# TLE987x register map
Vendor: Infineon; File version: 4.2
CPU: CM3 r0p0, little endian, no MPU, no FPU, 4 interrupt priority bits
Registers are 32-bit, read-write, reset 0x0 unless marked. A register's access mark holds for its fields unless they carry their own. Offsets are from the block's base; [hi:lo] are bit positions; {n}, {i} and the like mark numbered series; 'fields as' and 'values as' point back to an identical list.

## SCU — System Control Unit
Base 0x50005000
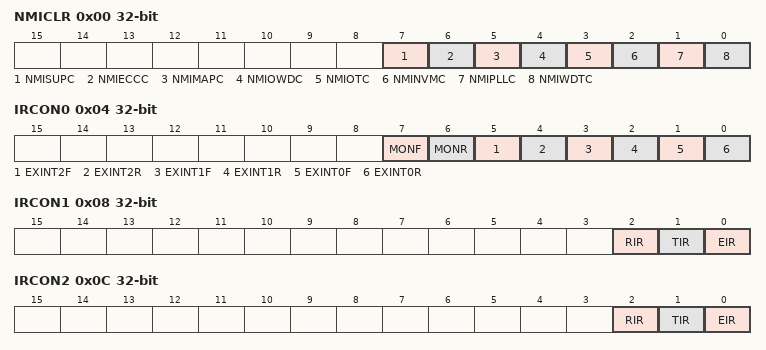
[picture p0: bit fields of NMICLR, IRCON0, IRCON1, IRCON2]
0x00 NMICLR wo — NMI Clear Register, RESET_TYPE_3
  [7] NMISUPC — Supply Prewarning NMI Clear
    0=Supply NMI is not cleared; 1=Supply NMI is cleared
  [6] NMIECCC — ECC Error NMI Clear
    0=ECC Error NMI is not cleared; 1=ECC Error NMI is cleared
  [5] NMIMAPC — NVM Map Error NMI Clear
    0=NVM Map Error NMI is not cleared; 1=NVM Map Error NMI is cleared
  [4] NMIOWDC — Oscillator Watchdog NMI Clear
    0=Oscillator watchdog NMI is not cleared; 1=Oscillator watchdog NMI is cleared
  [3] NMIOTC — NMI OT Clear
    0=NMI OT is not cleared; 1=NMI OT is cleared
  [2] NMINVMC — NVM Operation Complete NMI Clear
    0=NVM operation complete NMI is not cleared; 1=NVM operation complete NMI is cleared
  [1] NMIPLLC — PLL Loss of Lock NMI Clear
    0=PLL Loss of Lock NMI is not cleared; 1=PLL Loss of Lock NMI is cleared
  [0] NMIWDTC — Watchdog Timer NMI Clear
    0=WDT NMI is not cleared; 1=WDT NMI is cleared
0x04 IRCON0 ro — Interrupt Request Register 0, RESET_TYPE_3
  [7] MONF — Interrupt Flag for External Interrupt MON on falling edge
    0=Interrupt on falling edge event has not occurred; 1=Interrupt on falling edge event has occurred
  [6] MONR — Interrupt Flag for External Interrupt MON on rising edge
    0=Interrupt on rising edge event has not occurred; 1=Interrupt on rising edge event has occurred
  [5] EXINT2F — Interrupt Flag for External Interrupt 2x on falling edge
    values as MONF
  [4] EXINT2R — Interrupt Flag for External Interrupt 2x on rising edge
    values as MONR
  [3] EXINT1F — Interrupt Flag for External Interrupt 1x on falling edge
    values as MONF
  [2] EXINT1R — Interrupt Flag for External Interrupt 1x on rising edge
    values as MONR
  [1] EXINT0F — Interrupt Flag for External Interrupt 0x on falling edge
    values as MONF
  [0] EXINT0R — Interrupt Flag for External Interrupt 0x on rising edge
    values as MONR
0x08 IRCON1 ro — Interrupt Request Register 1, RESET_TYPE_3
  [all] fields
    0=Interrupt event has not occurred; 1=Interrupt event has occurred
  [2] RIR — Receive Interrupt Flag for SSC1
  [1] TIR — Transmit Interrupt Flag for SSC1
  [0] EIR — Error Interrupt Flag for SSC1
0x0C IRCON2 ro — Interrupt Request Register 2, RESET_TYPE_3
  [all] fields
    values as the fields of IRCON1
  [2] RIR — Receive Interrupt Flag for SSC2
  [1] TIR — Transmit Interrupt Flag for SSC2
  [0] EIR — Error Interrupt Flag for SSC2
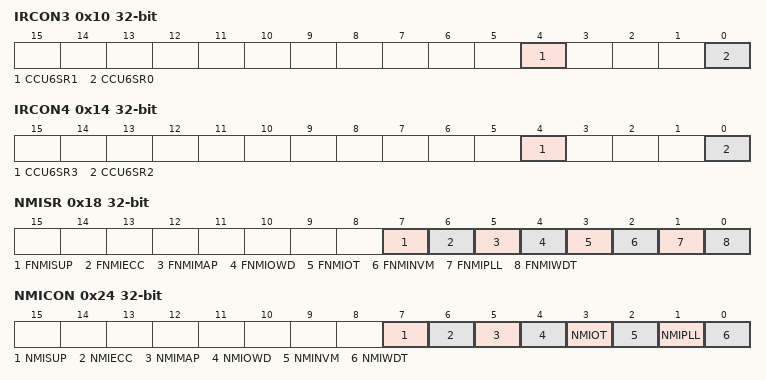
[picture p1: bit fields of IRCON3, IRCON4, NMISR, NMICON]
0x10 IRCON3 ro — Interrupt Request Register 3, RESET_TYPE_3
  [4] CCU6SR1 — Interrupt Flag 1 for CCU6
    values as the fields of IRCON1
  [0] CCU6SR0 — Interrupt Flag 0 for CCU6
    values as the fields of IRCON1
0x14 IRCON4 ro — Interrupt Request Register 4, RESET_TYPE_3
  [4] CCU6SR3 — Interrupt Flag 3 for CCU6
    values as the fields of IRCON1
  [0] CCU6SR2 — Interrupt Flag 2 for CCU6
    values as the fields of IRCON1
0x18 NMISR ro — NMI Status Register, RESET_TYPE_4
  [7] FNMISUP — Supply Prewarning NMI Flag
    0=No supply prewarning NMI has occurred; 1=Supply prewarning has occurred
  [6] FNMIECC — ECC Error NMI Flag
    0=No uncorrectable ECC error has occurred on NVM, XRAM; 1=Uncorrectable ECC error has occurred on NVM, RAM
  [5] FNMIMAP — NVM Map Error NMI Flag
    0=No NVM Map Error NMI has occurred; 1=NVM Map Error has occurred
  [4] FNMIOWD — Oscillator Watchdog or MI_CLK Watchdog NMI Flag
    0=No oscillator / MI_CLK watchdog NMI has occurred; 1=Oscillator / MI_CLK watchdog event has occurred
  [3] FNMIOT — Over-temperature NMI Flag
    0=No OT NMI has occurred; 1=OT NMI event has occurred
  [2] FNMINVM — NVM Operation Complete NMI Flag
    0=No NVM NMI has occurred; 1=NVM operation complete event has occurred
  [1] FNMIPLL — PLL NMI Flag
    0=No PLL NMI has occurred; 1=PLL loss-of-lock has occurred
  [0] FNMIWDT — Watchdog Timer NMI Flag
    0=No watchdog NMI has occurred; 1=WDT prewarning has occurred
0x1C IEN0 — Interrupt Enable Register 0, RESET_TYPE_4
  [7] EA — Global Interrupt Mask
    0=All pending interrupt requests (except NMI) are blocked from the core; 1=Pending interrupt requests are not blocked from the core
0x24 NMICON — NMI Control Register, RESET_TYPE_4
  [7] NMISUP — Supply Prewarning NMI Enable
    0=Supply NMI is disabled; 1=Supply NMI is enabled
  [6] NMIECC — ECC Error NMI Enable
    0=ECC Error NMI is disabled; 1=ECC Error NMI is enabled
  [5] NMIMAP — NVM Map Error NMI Enable
    0=NVM Map Error NMI is disabled; 1=NVM Map Error NMI is enabled
  [4] NMIOWD — Oscillator Watchdog NMI Enable
    0=Oscillator watchdog NMI is disabled; 1=Oscillator watchdog NMI is enabled
  [3] NMIOT — NMI OT Enable
    0=NMI OT is disabled; 1=NMI OT is enabled
  [2] NMINVM — NVM Operation Complete NMI Enable
    0=NVM operation complete NMI is disabled; 1=NVM operation complete NMI is enabled
  [1] NMIPLL — PLL Loss of Lock NMI Enable
    0=PLL Loss of Lock NMI is disabled; 1=PLL Loss of Lock NMI is enabled
  [0] NMIWDT — Watchdog Timer NMI Enable
    0=WDT NMI is disabled; 1=WDT NMI is enabled
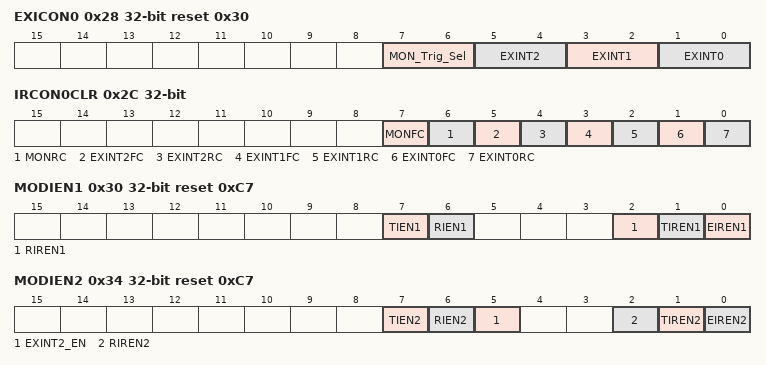
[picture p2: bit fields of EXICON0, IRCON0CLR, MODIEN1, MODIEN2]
0x28 EXICON0 reset 0x30 — External Interrupt Control Register 0, RESET_TYPE_3
  [7:6] MON_Trig_Sel — MON Input Trigger Select
    0=external interrupt MON is disabled; 1=Interrupt on rising edge; 2=Interrupt on falling edge; 3=Interrupt on both rising and falling edge
  [5:4] EXINT2 — External Interrupt 2 Trigger Select
    0=external interrupt 2 is disabled; 1=Interrupt on rising edge; 2=Interrupt on falling edge; 3=Interrupt on both rising and falling edge
  [3:2] EXINT1 — External Interrupt 1 Trigger Select
    0=external interrupt 1 is disabled; 1=Interrupt on rising edge; 2=Interrupt on falling edge; 3=Interrupt on both rising and falling edge
  [1:0] EXINT0 — External Interrupt 0 Trigger Select
    0=external interrupt 0 is disabled; 1=Interrupt on rising edge; 2=Interrupt on falling edge; 3=Interrupt on both rising and falling edge
0x2C IRCON0CLR wo — Interrupt Request 0 Clear Register, RESET_TYPE_3
  [7] MONFC — Interrupt Flag for External Interrupt MON on falling edge clear
    0=Interrupt on falling edge event is not cleared; 1=Interrupt on falling edge event is cleared
  [6] MONRC — Interrupt Flag for External Interrupt MON on rising edge clear
    0=Interrupt on rising edge event is not cleared; 1=Interrupt on rising edge event is cleared
  [5] EXINT2FC — Interrupt Flag for External Interrupt 2x on falling edge clear
    values as MONFC
  [4] EXINT2RC — Interrupt Flag for External Interrupt 2x on rising edge clear
    values as MONRC
  [3] EXINT1FC — Interrupt Flag for External Interrupt 1x on falling edge clear
    values as MONFC
  [2] EXINT1RC — Interrupt Flag for External Interrupt 1x on rising edge clear
    values as MONRC
  [1] EXINT0FC — Interrupt Flag for External Interrupt 0x on falling edge clear
    values as MONFC
  [0] EXINT0RC — Interrupt Flag for External Interrupt 0x on rising edge clear
    values as MONRC
0x30 MODIEN1 reset 0xC7 — Peripheral Interrupt Enable Register 1, RESET_TYPE_3
  [7] TIEN1 — UART 1 Transmit Interrupt Enable
    0=Transmit interrupt is disabled; 1=Transmit interrupt is enabled
  [6] RIEN1 — UART 1 Receive Interrupt Enable
    0=Receive interrupt is disabled; 1=Receive interrupt is enabled
  [2] RIREN1 — SSC 1 Receive Interrupt Enable
    values as RIEN1
  [1] TIREN1 — SSC 1 Transmit Interrupt Enable
    values as TIEN1
  [0] EIREN1 — SSC 1 Error Interrupt Enable
    0=Error interrupt is disabled; 1=Error interrupt is enabled
0x34 MODIEN2 reset 0xC7 — Peripheral Interrupt Enable Register 2, RESET_TYPE_3
  [7] TIEN2 — UART 2 Transmit Interrupt Enable
    values as MODIEN1.TIEN1
  [6] RIEN2 — UART 2 Receive Interrupt Enable
    values as MODIEN1.RIEN1
  [5] EXINT2_EN — External Interrupt 2 Enable
    0=External interrupt is disabled; 1=External interrupt is enabled
  [2] RIREN2 — SSC 2 Receive Interrupt Enable
    values as MODIEN1.RIEN1
  [1] TIREN2 — SSC 2 Transmit Interrupt Enable
    values as MODIEN1.TIEN1
  [0] EIREN2 — SSC 2 Error Interrupt Enable
    0=Error interrupt is disabled; 1=Error interrupt is enabled
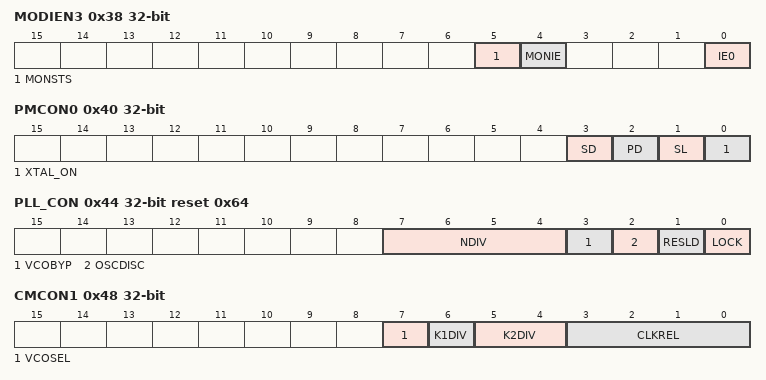
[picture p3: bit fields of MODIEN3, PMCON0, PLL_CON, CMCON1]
0x38 MODIEN3 access per field — Peripheral Interrupt Enable Register 3, RESET_TYPE_3
  [5] MONSTS ro — MON Input Status
    0=Status zero; 1=Status one
  [4] MONIE rw — MON Interrupt Enable
    0=disabled; 1=enabled
  [0] IE0 rw — External Interrupt Enable
    0=disabled; 1=enabled
0x3C MODIEN4 — Peripheral Interrupt Enable Register 4, RESET_TYPE_3
  [0] IE1 — External Interrupt Enable
    0=disabled; 1=enabled
0x40 PMCON0 — Power Mode Control Register 0, RESET_TYPE_3
  [3] SD — Slow Down Mode Enable. Active High.
    0=DISABLED (Slow Down disabled); 1=ENABLED (Slow Down enabled)
  [2] PD — Power Down Mode Enable. Active High.
    0=DISABLED (Power Down disabled); 1=ENABLED (Power Down enabled)
  [1] SL — Sleep Mode Enable. Active High.
    0=DISABLED (Sleep Mode disabled); 1=ENABLED (Sleep Mode enabled)
  [0] XTAL_ON — OSC_HP Operation in Power Down Mode
    0=OSC_HP (XTAL) will be put to Power Down mode by hardware in power save mode; 1=OSC_HP (XTAL) continues to operate in Power Down mode, if enabled by SCU_OSC_CON.XPD
0x44 PLL_CON access per field reset 0x64 — PLL Control Register, RESET_TYPE_4
  [7:4] NDIV rw — PLL N-Divider
    0=N = 8; 1=N = 9; 2=N = 10; 3=N = 12; 4=N = 14; 5=N = 15; 6=N = 16 (default); 7=N = 18; 8=N = 20; 9=N = 21; 10=N = 22; {v}=N = {v+13} (v=11..15)
  [3] VCOBYP rw — PLL VCO Bypass Mode Select
    0=Normal (or freerunning) operation (default); 1=Prescaler Mode; VCO is bypassed (PLL output clock is derived from input clock divided by K1-divider)
  [2] OSCDISC rw — Oscillator Disconnect
    0=Oscillator is connected to the PLL; 1=Oscillator is disconnected to the PLL
  [1] RESLD rw — Restart Lock Detection
    0=No effect; 1=Reset lock flag and restart lock detection
  [0] LOCK ro — PLL Lock Status Flag
    0=The frequency difference of fREF and fDIV is greater than allowed. The VCO part of the PLL can not lock on a target frequency.; 1=The frequency difference of fREF and fDIV is small enough to enable a stable VCO operation
0x48 CMCON1 — Clock Control Register 1, RESET_TYPE_4
  [7] VCOSEL — VCOSEL Setting
    0=VCOSEL = 0; 1=VCOSEL = 1
  [6] K1DIV — PLL K1-Divider
    0=K1 = 2; 1=K1 = 1
  [5:4] K2DIV — PLL K2-Divider
    {v}=K2 = {v+2} (v=0..3)
  [3:0] CLKREL — Slow Down Clock Divider for fCCLK Generation
    0=fsys; 1=fsys/2; 2=fsys/3; 3=fsys/4; 4=fsys/8; 5=fsys/16; 6=fsys/24; 7=fsys/32; 8=fsys/48; 9=fsys/64; 10=fsys/96; 11=fsys/128; 12=fsys/192; 13=fsys/256; 14=fsys/384; 15=fsys/512
0x4C CMCON2 — Clock Control Register 2, RESET_TYPE_4
  [0] PBA0CLKREL — PBA0 Clock Divider
    0=divide by 1; 1=divide by 2
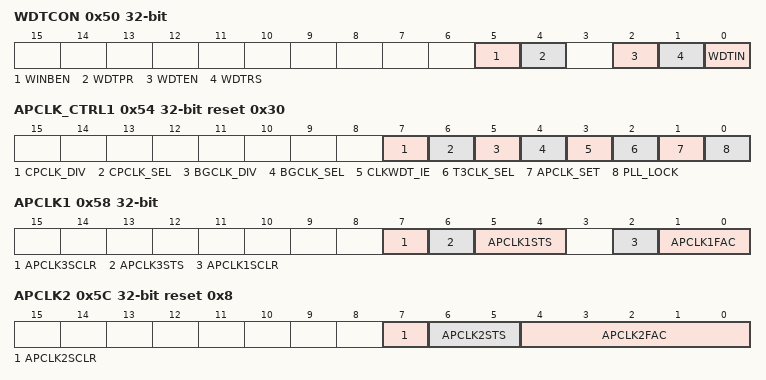
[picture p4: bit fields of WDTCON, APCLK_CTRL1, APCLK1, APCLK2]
0x50 WDTCON access per field — Watchdog Timer Control Register, RESET_TYPE_3
  [5] WINBEN rw — Watchdog Window-Boundary Enable
    0=Watchdog Window-Boundary feature is disabled. (default); 1=Watchdog Window-Boundary feature is enabled
  [4] WDTPR ro — Watchdog Prewarning Mode Flag
    0=Normal mode (default after reset); 1=The Watchdog is operating in Prewarning Mode
  [2] WDTEN rw — WDT Enable
    0=WDT is disabled; 1=WDT is enabled
  [1] WDTRS rw — WDT Refresh Start
    0=no_action (WDT not triggered); 1=refresh (WDT refresh is triggered)
  [0] WDTIN rw — Watchdog Timer Input Frequency Selection
    0=Input frequency is fPCLK/2; 1=Input frequency is fPCLK/128
0x54 APCLK_CTRL1 access per field reset 0x30 — Analog Peripheral Clock Control 1 Register, RESET_TYPE_4
  [7] CPCLK_DIV rw — Charge Pump Clock Divider
    0=divide by 2; 1=divide by 1
  [6] CPCLK_SEL rw — Charge Pump Clock Selection
    0=LP_CLK is selected; 1=fsys is selected
  [5] BGCLK_DIV rw — Bandgap Clock Divider
    0=divide by 2; 1=divide by 1
  [4] BGCLK_SEL rw — Bandgap Clock Selection
    0=LP_CLK is selected; 1=fsys is selected
  [3] CLKWDT_IE rw — Clock Watchdog Interrupt Enable
    0=Interrupt disabled; 1=Interrupt enabled
  [2] T3CLK_SEL rw — Timer 3 Clock Selection
    0=LP_CLK is selected; 1=MI_CLK is selected
  [1] APCLK_SET rw — Set and Overtake Flag for Clock Settings
    0=Clock Settings are ignored (previous values are hold); 1=Clock Settings Settings are overtaken
  [0] PLL_LOCK ro — PLL Lock Indicator
    1=locked (PLL has locked); 0=not_locked (PLL not locked)
0x58 APCLK1 access per field — Analog Peripheral Clock Register 1, RESET_TYPE_4
  [7] APCLK3SCLR rw — Analog Peripherals Clock Status Clear
    0=no_action (no change); 1=clear status
  [6] APCLK3STS ro — Loss of Clock Status
    0=No loss of clock; 1=Loss of Lock occured
  [5:4] APCLK1STS ro — Analog Peripherals Clock Status
    0=The MI_CLK clock is in the required range; 1=The MI_CLK clock exceeds the higher limit; 2=The MI_CLK clock exceeds the lower limit; 3=The MI_CLK clock is not inside the specified limit
  [2] APCLK1SCLR rw — Analog Peripherals Clock Status Clear
    0=no_action (no change); 1=clear status
  [1:0] APCLK1FAC rw — Analog Module Clock Factor
    {v}=Divide by {v+1} (v=0..3)
0x5C APCLK2 access per field reset 0x8 — Analog Peripheral Clock Register 2, RESET_TYPE_4
  [7] APCLK2SCLR rw — Analog Peripherals Clock Status Clear
    0=no_action (no change); 1=clear status
  [6:5] APCLK2STS ro — Analog Peripherals Clock Status
    0=The TFILT_CLK clock is in the required range; 1=The TFILT_CLK clock exceeds the higher limit; 2=The TFILT_CLK clock exceeds the lower limit; 3=The TFILT_CLK clock is not inside the specified limit
  [4:0] APCLK2FAC rw — Slow Down Clock Divider for TFILT_CLK Generation
    0=fsys; {v}=fsys/{v+1} (v=1..11); 30=fsys/31; 31=fsys/32
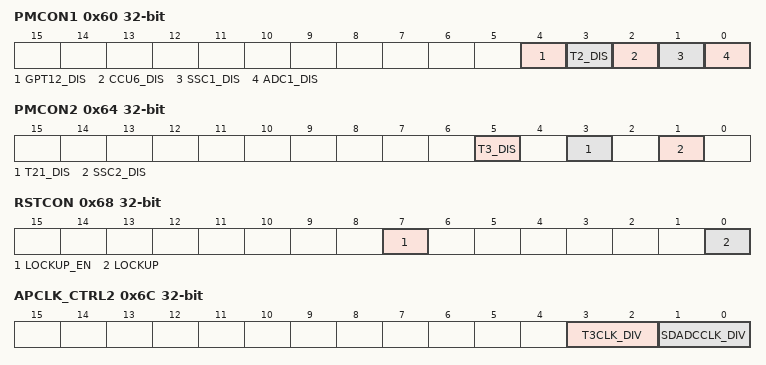
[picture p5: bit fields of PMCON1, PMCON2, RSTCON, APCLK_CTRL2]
0x60 PMCON1 — Peripheral Management Control Register 1, RESET_TYPE_3
  [4] GPT12_DIS — General Purpose Timer 12 Disable Request. Active high.
    0=GPT12is in normal operation. (default); 1=Request to disable the GPT12
  [3] T2_DIS — T2 Disable Request. Active high.
    0=T2 is in normal operation. (default); 1=Request to disable the T2
  [2] CCU6_DIS — CCU6 Disable Request. Active high.
    0=CCU6 is in normal operation. (default); 1=Request to disable the CCU6
  [1] SSC1_DIS — SSC1 Disable Request. Active high.
    0=SSC1 is in normal operation. (default); 1=Request to disable the SSC1
  [0] ADC1_DIS — ADC1 Disable Request. Active high.
    0=ADC1 is in normal operation. (default); 1=Request to disable the ADC
0x64 PMCON2 — Peripheral Management Control Register 2, RESET_TYPE_3
  [5] T3_DIS — T3 Disable Request. Active high.
    0=T3is in normal operation. (default); 1=Request to disable the T3
  [3] T21_DIS — T21 Disable Request. Active high.
    0=T21 is in normal operation. (default); 1=Request to disable the T21
  [1] SSC2_DIS — SSC2 Disable Request. Active high.
    0=SSC2 is in normal operation. (default); 1=Request to disable the SSC2
0x68 RSTCON — Reset Control Register, RESET_TYPE_3
  [7] LOCKUP_EN — Lockup Reset Enable Flag
    0=Lockup is disabled; 1=Lockup is enabled
  [0] LOCKUP — Lockup Flag
    0=Lockup Status not active; 1=Lockup Status active
0x6C APCLK_CTRL2 — Analog Peripheral Clock Control 2 Register, RESET_TYPE_4
  [3:2] T3CLK_DIV — Timer 3 Clock Divider
    0=divide by 1; 1=divide by 2; 2=divide by 4; 3=divide by 8
  [1:0] SDADCCLK_DIV — SD-ADC Clock Divider
    0=divide by 1; 1=divide by 2; 2=divide by 4; 3=divide by 8
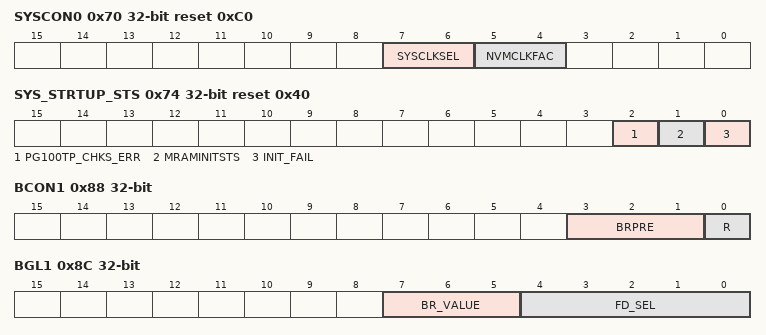
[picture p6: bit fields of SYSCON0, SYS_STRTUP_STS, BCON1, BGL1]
0x70 SYSCON0 reset 0xC0 — System Control Register 0, RESET_TYPE_4
  [7:6] SYSCLKSEL — System Clock Select
    0=The PLL clock output signal fPLL is used; 1=The direct clock input from fOSC is used; 2=The direct low-precision clock input from fLP_CLK is used; 3=The direct low-precision clock input from fLP_CLK is used
  [5:4] NVMCLKFAC — NVM Access Clock Factor
    {v}=Divide by {v+1} (v=0..3)
0x74 SYS_STRTUP_STS reset 0x40 — System Startup Status Register
  [2] PG100TP_CHKS_ERR — 100 TP Page Checksum Error
    0=pass (no checksum error detected); 1=fail (100TP checksum error detected)
  [1] MRAMINITSTS — Map RAM Initialization Status
    0=pass (Map RAM initialization pass); 1=fail (Map RAM initialization finished with fails)
  [0] INIT_FAIL — Initialization at startup failed
    0=pass (no error during startup detected); 1=fail (at least one error during startup detected)
0x78 WDTREL — Watchdog Timer Reload Register, RESET_TYPE_3
  [7:0] WDTREL — Watchdog Timer Reload Value
0x7C WDTWINB — Watchdog Window-Boundary Count, RESET_TYPE_3
  [7:0] WDTWINB — Watchdog Window-Boundary Count Value
0x80 WDTL ro — Watchdog Timer, Low Byte, RESET_TYPE_3
  [7:0] WDT — Watchdog Timer Current Value
0x84 WDTH ro — Watchdog Timer, High Byte, RESET_TYPE_3
  [7:0] WDT — Watchdog Timer Current Value
0x88 BCON1 — Baud Rate Control Register 1, RESET_TYPE_3
  [3:1] BRPRE — Prescaler Bit
    0=fDIV = fPCLK; 1=fDIV = fPCLK/2; 2=fDIV = fPCLK/4; 3=fDIV = fPCLK/8; 4=fDIV = fPCLK/16; 5=fDIV = fPCLK/32
  [0] R — Baud Rate Generator Run Control Bit
    0=Baud-rate generator disabled; 1=Baud-rate generator enabled
0x8C BGL1 — Baud Rate Timer/Reload Register, Low Byte 1, RESET_TYPE_3
  [7:5] BR_VALUE — Baud Rate Timer/Reload Value
  [4:0] FD_SEL — Fractional Divider Selection
0x90 BGH1 — Baud Rate Timer/Reload Register, High Byte, RESET_TYPE_3
  [7:0] BR_VALUE — Baud Rate Timer/Reload Value
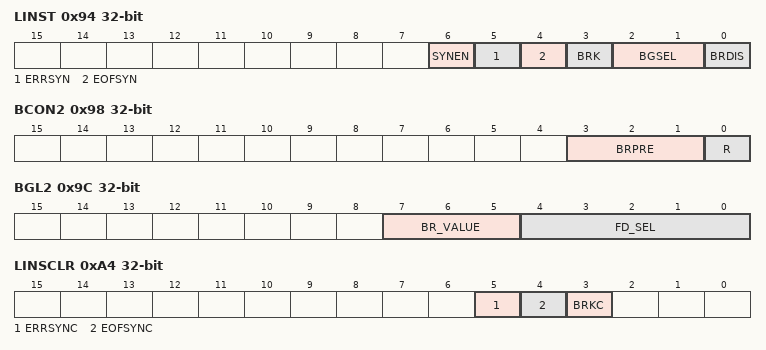
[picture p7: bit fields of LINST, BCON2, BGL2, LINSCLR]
0x94 LINST access per field — LIN Status Register, RESET_TYPE_3
  [6] SYNEN rw — End of SYN Byte and SYN Byte Error Interrupts Enable
    0=End of SYN Byte and SYN Byte Error Interrupts are not enabled; 1=End of SYN Byte and SYN Byte Error Interrupts are enabled
  [5] ERRSYN ro — SYN Byte Error Interrupt Flag
    0=Error is not detected in SYN Byte; 1=Error is detected in SYN Byte
  [4] EOFSYN ro — End of SYN Byte Interrupt Flag
    0=End of SYN Byte is not detected; 1=End of SYN Byte is detected
  [3] BRK ro — Break Field Flag
    0=Break Field is not detected; 1=Break Field is detected
  [2:1] BGSEL rw — Baud Rate Select for Detection
  [0] BRDIS rw — Baud Rate Detection Disable
    0=Break/Synch detection is enabled; 1=Break/Synch detection is disabled
0x98 BCON2 — Baud Rate Control Register 2, RESET_TYPE_3
  fields as BCON1
0x9C BGL2 — Baud Rate Timer/Reload Register, Low Byte 2, RESET_TYPE_3
  fields as BGL1
0xA0 BGH2 — Baud Rate Timer/Reload Register, High Byte, RESET_TYPE_3
  [7:0] BR_VALUE — Baud Rate Timer/Reload Value
0xA4 LINSCLR wo — LIN Status Clear Register, RESET_TYPE_3
  [5] ERRSYNC — SYN Byte Error Interrupt Flag
    0=Error in SYN Byte not cleared; 1=Error in SYN Byte cleared
  [4] EOFSYNC — End of SYN Byte Interrupt Flag Clear
    0=End of SYN Byte is not cleared; 1=End of SYN Byte is cleared
  [3] BRKC — Break Field Flag Clear
    0=Break Field is not cleared; 1=Break Field is cleared
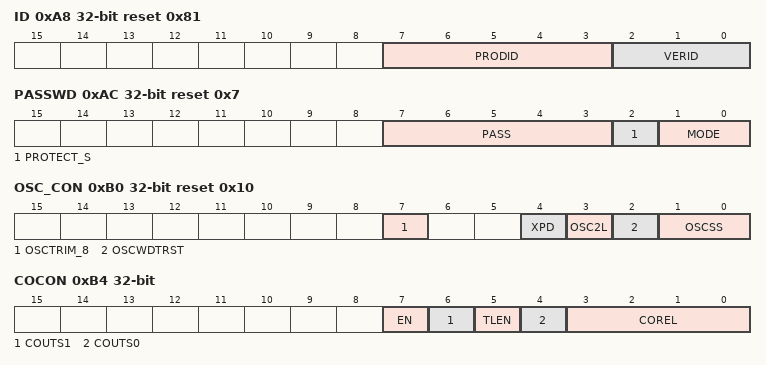
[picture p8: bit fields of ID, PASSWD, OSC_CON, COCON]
0xA8 ID ro reset 0x81 — Identity Register, RESET_TYPE_3
  [7:3] PRODID — Product ID
  [2:0] VERID — Version ID
0xAC PASSWD access per field reset 0x7 — Password Register, RESET_TYPE_3
  [7:3] PASS rw — Password Bits
    24=Enables writing of the bit field MODE; 19=Opens access to writing of all protected bits; 21=Closes access to writing of all protected bits
  [2] PROTECT_S ro — Bit-Protection Signal Status Bit
    0=Software is able to write to all protected bits; 1=Software is unable to write to any protected bits
  [1:0] MODE rw — Bit-Protection Scheme Control Bit
    0=Scheme Disabled; 3=Scheme Enabled (default)
0xB0 OSC_CON access per field reset 0x10 — OSC Control Register, RESET_TYPE_4
  [7] OSCTRIM_8 rw — OSC_PLL Trim Configuration Bit [8]
    0=trimming disabled; 1=trimming enabled
  [4] XPD rw — XTAL (OSC_HP) Power Down Control
    0=XTAL (OSC_HP) is not powered down; 1=XTAL (OSC_HP) is powered down
  [3] OSC2L ro — OSC-Too-Low Condition Flag
    0=fOSC is above threshold; 1=fOSC is below threshold
  [2] OSCWDTRST rw — Oscillator Watchdog Reset
    0=No effect; 1=Reset OSC2L flag and restart the oscillator watchdog of the PLL
  [1:0] OSCSS rw — Oscillator Source Select
    0=PLL internal oscillator OSC_PLL (fINT) is selected synchronously as fR; 1=XTAL (fOSC from OSC_HP) is selected synchronously as fR; 2=PLL internal oscillator OSC_PLL (fINT) is selected asynchronously as fR; 3=PLL internal oscillator OSC_PLL (fINT) is selected asynchronously as fR
0xB4 COCON — Clock Output Control Register, RESET_TYPE_4
  [7] EN — CLKOUT Enable
    0=No external clock signal is provided; 1=The configured external clock signal is provided
  [6] COUTS1 — Clock Out Source Select Bit 1
    0=fCCLK is selected; 1=Based on setting of COUTS0
  [5] TLEN — Toggle Latch Enable
    0=Toggle Latch is disabled. Clock output frequency is chosen by the bit field COREL.; 1=Toggle Latch is enabled. Clock output frequency is half of the frequency that is chosen by the bit field COREL. The resulting output frequency has 50 percent70 duty cycle.
  [4] COUTS0 — Clock Out Source Select Bit 0
    0=Oscillator output frequency is selected; 1=Clock output frequency is chosen by the bit field COREL
  [3:0] COREL — Clock Output Divider
    0=fsys; 1=fsys/2; 2=fsys/3; 3=fsys/4; 4=fsys/6; 5=fsys/8; 6=fsys/10; 7=fsys/12; 8=fsys/14; 9=fsys/16; 10=fsys/18; 11=fsys/20; 12=fsys/24; 13=fsys/32; 14=fsys/36; 15=fsys/40
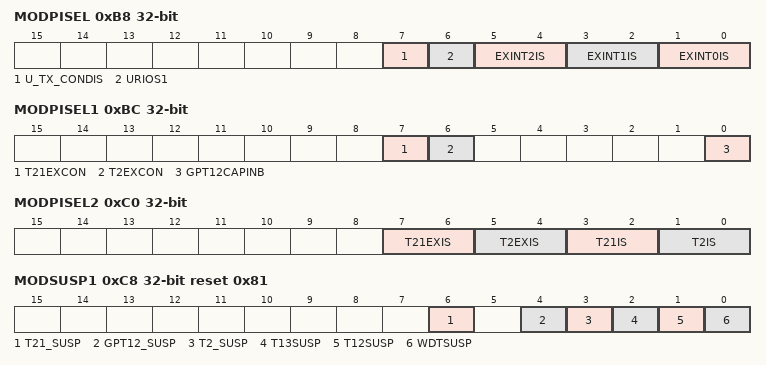
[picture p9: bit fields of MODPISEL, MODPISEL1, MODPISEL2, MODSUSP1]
0xB8 MODPISEL — Peripheral Input Select Register, RESET_TYPE_3
  [7] U_TX_CONDIS — UART1 TxD Connection Disable
    0=UART1-TX-Output -LIN Transmitter TX Input Connection available; 1=UART1-TX-Output -LIN Transmitter TX Input Connection not available (can be stimulated by external port pin)
  [6] URIOS1 — UART1 Input/Output Select
    0=UART1 Receiver Input RXD1_0 (Connection to LIN is available); 1=UART1 Receiver Input RXD1_1 (Connection to LIN is not available)
  [5:4] EXINT2IS — External Interrupt 2 Input Select
    0=External Interrupt Input EXINT2_0 is selected (P2.7); 1=External Interrupt Input EXINT2_1 is selected (P1.4); 2=External Interrupt Input EXINT2_2 is selected (P0.4); 3=External Interrupt Input EXINT2_3 is selected (P0.0)
  [3:2] EXINT1IS — External Interrupt 1 Input Select
    0=External Interrupt Input EXINT1_0 is selected (P1.1); 1=External Interrupt Input EXINT1_1 is selected (P1.3); 2=External Interrupt Input EXINT1_2 is selected (P1.0); 3=External Interrupt Input EXINT1_3 is selected (P2.4)
  [1:0] EXINT0IS — External Interrupt 0 Input Select
    0=External Interrupt Input EXINT0_0 is selected (P2.0); 1=External Interrupt Input EXINT0_1 is selected (P1.2); 2=External Interrupt Input EXINT0_2 is selected (P0.1); 3=External Interrupt Input EXINT0_3 is selected (P2.3)
0xBC MODPISEL1 — Peripheral Input Select Register 1, RESET_TYPE_3
  [7] T21EXCON — Timer 21 External Input Control
    0=Timer 21 Input T21EX is selected by bit field MODPISEL.T2EXIS; 1=Timer 21 Input T21EX is connected to signal from analog subsystem
  [6] T2EXCON — Timer 2 External Input Control
    0=Timer 2 Input T2EX is selected by bit field MODPISEL.T2EXIS; 1=Timer 2 Input T2EX is connected to signal from analog subsystem
  [0] GPT12CAPINB — GPT12 CAPINB Input Control
    0=GPT12 CAPINB Input is connected to P0.3; 1=GPT12 CAPINB Input is connected to BEMF comparator
0xC0 MODPISEL2 — Peripheral Input Select Register 2, RESET_TYPE_3
  [7:6] T21EXIS — Timer 21 External Input Select
    {v}=Timer 21 Input T21EX_{v} is selected (v=0..3)
  [5:4] T2EXIS — Timer 2 External Input Select
    0=Timer 2 Input T2EX_0 is selected; 1=Timer 2 Input T2EX_1 is selected
  [3:2] T21IS — Timer 21 Input Select
    0=Timer 21 Input T21_0 is selected; 1=Timer 21 Input T21_1 is selected; 2=Timer 21 Input T21_2 is selected
  [1:0] T2IS — Timer 2 Input Select
    0=Timer 2 Input T2_0 is selected
0xC4 MODPISEL3 — Peripheral Input Select Register, RESET_TYPE_3
  [6] URIOS2 — UART2 Input/Output Select
    0=UART2 Receiver Input RXD2_0 and Transmitter Output TXD2_0 is selected; 1=UART2 Receiver Input RXD2_1 and Transmitter Output TXD2_1 is selected
0xC8 MODSUSP1 reset 0x81 — Module Suspend Control Register 1, RESET_TYPE_3
  [6] T21_SUSP — Timer21 Debug Suspend Bit
    0=Timer21 will not be suspended; 1=Timer21 will be suspended
  [4] GPT12_SUSP — GPT12 Debug Suspend Bit
    0=GPT12 will not be suspended; 1=GPT12 will be suspended
  [3] T2_SUSP — Timer2 Debug Suspend Bit
    0=Timer2 will not be suspended; 1=Timer2 will be suspended
  [2] T13SUSP — Timer 13 Debug Suspend Bit
    0=Timer 13 in Capture/Compare Unit will not be suspended; 1=Timer 13 in Capture/Compare Unit will be suspended
  [1] T12SUSP — Timer 12 Debug Suspend Bit
    0=Timer 12 in Capture/Compare Unit will not be suspended; 1=Timer 12 in Capture/Compare Unit will be suspended
  [0] WDTSUSP — SCU Watchdog Timer Debug Suspend Bit
    0=WDT will not be suspended; 1=WDT will be suspended
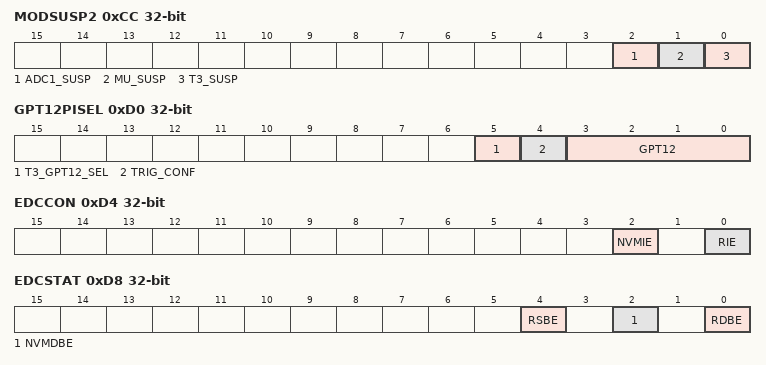
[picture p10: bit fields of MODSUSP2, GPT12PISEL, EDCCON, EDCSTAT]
0xCC MODSUSP2 — Module Suspend Control Register 2, RESET_TYPE_3
  [2] ADC1_SUSP — ADC1 Unit Debug Suspend Bit
    0=ADC1 will not be suspended; 1=ADC1 will be suspended
  [1] MU_SUSP — Measurement Unit Debug Suspend Bit
    0=MU will not be suspended; 1=MU will be suspended
  [0] T3_SUSP — Measurement Unit Debug Suspend Bit
    0=Timer 3 will not be suspended; 1=Timer 3 will be suspended
0xD0 GPT12PISEL — GPT12 Peripheral Input Select Register, RESET_TYPE_3
  [5] T3_GPT12_SEL — CCU6_INT_SEL.
    0=CCU6_INT is triggered by Timer 3; 1=CCU6_INT is triggered by GPT12PISEL.GPT12
  [4] TRIG_CONF — CCU6 Trigger Configuration.
    0=Trigger is just for one measurement (default); 1=Trigger is present until next input edge (selected by GPT12) - continuos measurement
  [3:0] GPT12 — GPT12 TIN3B / TIN4D Input Select
    0=CC60; 1=CC61; 2=CC62; 3=T12 ZM; 4=T12 PM; 5=T12 CM0; 6=T12 CM1; 7=T12 CM2; 8=T13 PM; 9=T13 ZM; 10=T13 CM; 11=any pos or neg edge on CC60/61/62; {v}=RES (v=12..15)
0xD4 EDCCON — Error Detection and Correction Control Register, RESET_TYPE_3
  [2] NVMIE — NVM Double Bit ECC Error Interrupt Enable
    0=No NMI is generated when a double bit ECC error occurs reading NVM; 1=An NMI is generated when a double bit ECC error occurs reading NVM
  [0] RIE — RAM Double Bit ECC Error Interrupt Enable
    0=No NMI is generated when a double bit ECC error occurs reading RAM; 1=An NMI is generated when a double bit ECC error occurs reading RAM
0xD8 EDCSTAT ro — Error Detection and Correction Status Register, RESET_TYPE_4
  [4] RSBE — RAM Single Bit Error
    0=No single bit error on RAM has occured; 1=A single bit error on RAM has occured
  [2] NVMDBE — NVM Double Bit Error
    0=No double bit error on NVM has occured; 1=A double bit error on NVM has occured
  [0] RDBE — RAM Double Bit Error
    0=No double bit error on RAM has occured; 1=A double bit error on RAM has occured
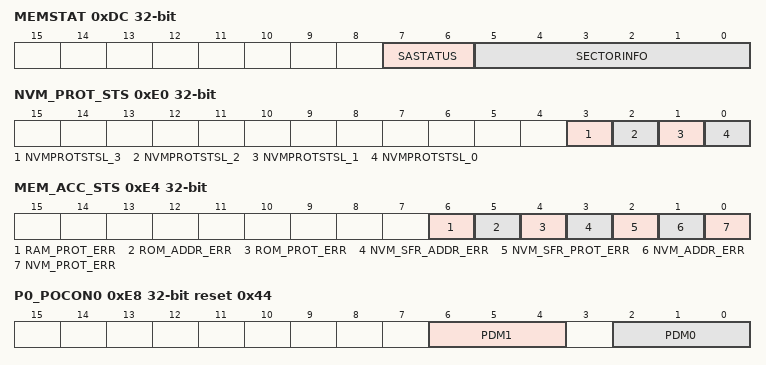
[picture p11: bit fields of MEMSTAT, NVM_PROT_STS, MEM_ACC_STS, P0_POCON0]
0xDC MEMSTAT — Memory Status Register, RESET_TYPE_3
  [7:6] SASTATUS — Service Algorithm Status
    0=Depending on SECTORINFO, there are two possible outcomes: For SECTORINFO = 00H, NVM initialization is successful and no SA is executed. For SECTORINFO = values other than 00H, SA execution is successful and only one map error is fixed.; 1=SA execution is successful. More than one mapping error is fixed.; 2=SA execution is not successful. Map error exists in one sector.; 3=SA execution is not successful. At least one sector failed (this includes also the case where a sector is repaired but another sector is still failing).
  [5:0] SECTORINFO — Sector Information
0xE0 NVM_PROT_STS — NVM Protection Status Register, RESET_TYPE_4
  [3] NVMPROTSTSL_3 — NVM Protection Status Register Low Flags
    0=The data in sectors of the linearly mapped area can not be read; 1=The data in sectors of the linearly mapped area can be read
  [2] NVMPROTSTSL_2 — NVM Protection Status Register Low Flags
    0=The data in sectors of the non-linearly mapped area can not be read; 1=The data in sectors of the non-linearly mapped area can be read
  [1] NVMPROTSTSL_1 — NVM Protection Status Register Low Flags
    0=The data in sectors of the linearly mapped area can not be changed; 1=The data in sectors of the linearly mapped area can be changed
  [0] NVMPROTSTSL_0 — NVM Protection Status Register Low Flags
    0=The data in sectors of the non-linearly mapped area can not be changed; 1=The data in sectors of the non-linearly mapped area can be changed
0xE4 MEM_ACC_STS ro — Memory Access Status Register, RESET_TYPE_3
  [all] fields
    0=No Protection error; 1=Protection error
  [6] RAM_PROT_ERR — RAM Access Protection
  [5] ROM_ADDR_ERR — ROM Address Protection
  [4] ROM_PROT_ERR — ROM Access Protection
  [3] NVM_SFR_ADDR_ERR — NVM SFR Address Protection
  [2] NVM_SFR_PROT_ERR — NVM SFR Access Protection
  [1] NVM_ADDR_ERR — NVM Address Protection
  [0] NVM_PROT_ERR — NVM Access Protection
0xE8 P0_POCON0 reset 0x44 — Port Output Control Register, RESET_TYPE_3
  [6:4] PDM1 — P0.1 Port Driver Mode
    3=Weak driver; 4=Medium driver; 5=Medium driver; 6=Medium driver; 7=Weak driver
  [2:0] PDM0 — P0.0 Port Driver Mode
    values as PDM1
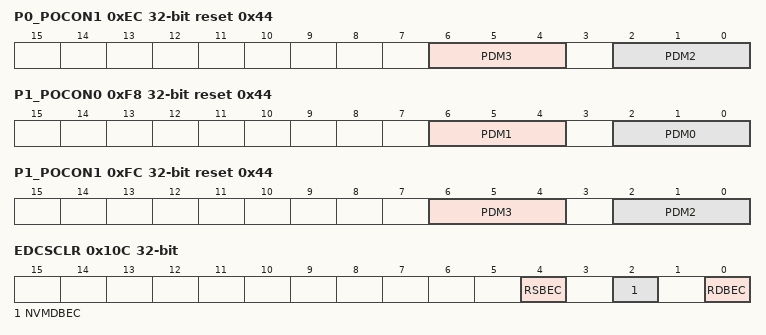
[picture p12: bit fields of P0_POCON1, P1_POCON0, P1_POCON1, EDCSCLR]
0xEC P0_POCON1 reset 0x44 — Port Output Control Register, RESET_TYPE_3
  [6:4] PDM3 — P0.3 Port Driver Mode
    values as P0_POCON0.PDM1
  [2:0] PDM2 — P0.2 Port Driver Mode
    0=Strong driver and sharp edge mode; 1=Strong driver and medium edge mode; 2=Strong driver and soft edge mode; 3=Weak driver; 4=Medium driver; 5=Medium driver; 6=Medium driver; 7=Weak driver
0xF0 P0_POCON2 reset 0x44 — Port Output Control Register, RESET_TYPE_3
  [2:0] PDM4 — P0.4 Port Driver Mode
    values as P0_POCON0.PDM1
0xF4 TCCR reset 0x3 — Temperature Compensation Control Register, RESET_TYPE_3
  [1:0] TCC — Temperature Compensation Control
    0=TJ: -40 oC to 0 oC; 1=TJ: 0 oC to 40 oC; 2=TJ: 40 oC to 80 oC; 3=TJ: 80 oC to 150 oC
0xF8 P1_POCON0 reset 0x44 — Port Output Control Register, RESET_TYPE_3
  [6:4] PDM1 — P1.1 Port Driver Mode
    values as P0_POCON0.PDM1
  [2:0] PDM0 — P1.0 Port Driver Mode
    values as P0_POCON0.PDM1
0xFC P1_POCON1 reset 0x44 — Port Output Control Register, RESET_TYPE_3
  [6:4] PDM3 — P1.3 Port Driver Mode
    values as P0_POCON1.PDM2
  [2:0] PDM2 — P1.2 Port Driver Mode
    values as P0_POCON0.PDM1
0x100 P1_POCON2 reset 0x4 — Port Output Control Register, RESET_TYPE_3
  [2:0] PDM4 — P1.4 Port Driver Mode
    values as P0_POCON1.PDM2
0x10C EDCSCLR wo — Error Detection and Correction Status Clear Register, RESET_TYPE_3
  [4] RSBEC — RAM Single Bit Error Clear
    0=A single bit error on RAM is not cleared; 1=A single bit error on RAM is cleared
  [2] NVMDBEC — NVM Double Bit Error Clear
    0=A double bit error on NVM is not cleared; 1=A double bit error on NVM is cleared
  [0] RDBEC — RAM Double Bit Error Clear
    0=A double bit error on RAM is not cleared; 1=A double bit error on RAM is cleared
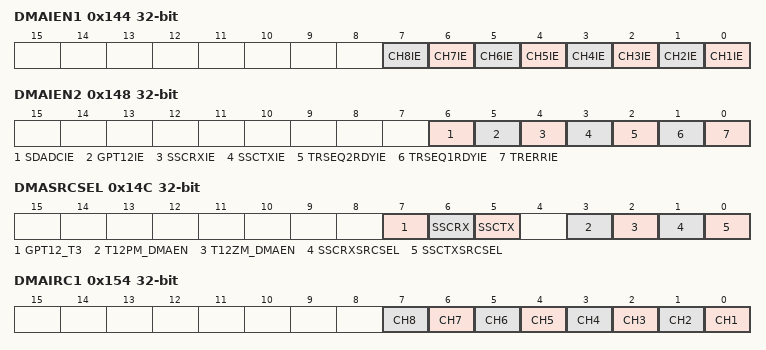
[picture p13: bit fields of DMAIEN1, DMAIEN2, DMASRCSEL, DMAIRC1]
0x144 DMAIEN1 — DMA Interrupt Enable Register 1, RESET_TYPE_3
  [all] fields
    0=Interrupt is disabled; 1=Interrupt is enabled
  [n-1] CH{n}IE (n=1..8) — DMA Channel {n+3} Interrupt Enable (ADC1 Channel {n-1})
0x148 DMAIEN2 — DMA Interrupt Enable Register 2, RESET_TYPE_3
  [all] fields
    0=Interrupt is disabled; 1=Interrupt is enabled
  [6] SDADCIE — DMA Channel 13 Interrupt Enable (SDADC)
  [5] GPT12IE — DMA Channel 12 Interrupt Enable (GPT12/Timer3)
  [4] SSCRXIE — DMA Channel 3 Interrupt Enable (SSCx Receive)
  [3] SSCTXIE — DMA Channel 2 Interrupt Enable (SSCx Transmit)
  [2] TRSEQ2RDYIE — DMA Channel 1 Interrupt Enable (ADC1 ESM)
  [1] TRSEQ1RDYIE — DMA Channel 0 Interrupt Enable (ADC1 Sequence)
  [0] TRERRIE — DMA Transfer Error Interrupt Enable
0x14C DMASRCSEL access per field — DMA Source Selection Register, RESET_TYPE_3
  [7] GPT12_T3 ro — DMA Channel 12 Request (GPT12E, Timer3)
    0=GPT12_T3 Transfer DMA Request not present; 1=GPT12_T3 Transfer DMA Request present
  [6] SSCRX ro — DMA Channel 3 Request (SSCx Receive)
    0=SSC Receive DMA Request not present; 1=SSC Receive DMA Request present
  [5] SSCTX ro — DMA Channel 2 Request (SSCx Transmit)
    0=SSC Transmit DMA Request not present; 1=SSC Transmit DMA Request present
  [3] T12PM_DMAEN rw — CC6_T12_PM (Period Match) DMA muxer, DMA channel 11
    0=ADC1 Channel 7 used as trigger for DMA Channel 11; 1=CCU6 T12_PM used as trigger for DMA channel 11
  [2] T12ZM_DMAEN rw — CC6_T12_ZM (Zero Match) DMA muxer, DMA channel 9
    0=ADC1 Channel 5 used as trigger for DMA Channel 9; 1=CCU6 T12_ZM used as trigger for DMA Channel 9
  [1] SSCRXSRCSEL rw — SSCx Receive Source Select
    0=SSC1 Receive as DMA input is enabled; 1=SSC2 Receive as DMA input is enabled
  [0] SSCTXSRCSEL rw — SSCx Transmit Source Select
    0=SSC1 Transmit as DMA input is enabled; 1=SSC2 Transmit as DMA input is enabled
0x154 DMAIRC1 ro — DMA Interrupt Control Register 1, RESET_TYPE_3
  [n-1] CH{n} (n=1..8) — DMA Channel {n+3} Interrupt Status (ADC1 Channel {n-1})
    0=No DMA Channel {n+3} Interrupt has occurred; 1=DMA Channel {n+3} Interrupt has occurred
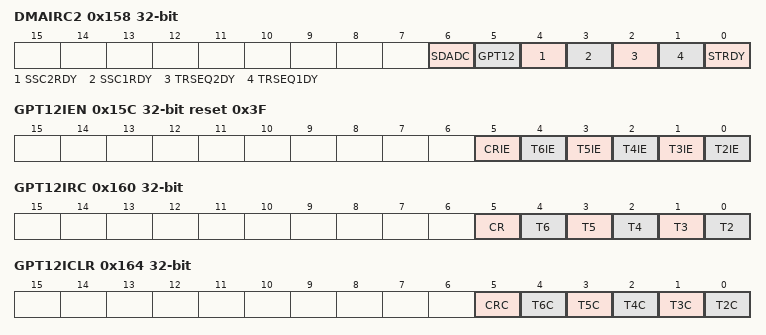
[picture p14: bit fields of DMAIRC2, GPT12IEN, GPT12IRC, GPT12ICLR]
0x158 DMAIRC2 ro — ADC1 Interrupt Control Register 2, RESET_TYPE_3
  [6] SDADC — DMA Channel 13 Interrupt Status (SDADC)
    0=No DMA SDADC Transfer Ready Interrupt has occurred; 1=DMA SDADC Transfer Ready Interrupt has occurred
  [5] GPT12 — DMA Channel 12 Interrupt Status (GPT12/Timer3)
    0=No DMA GPT12 Transfer Ready Interrupt has occurred; 1=DMA GPT12 Transfer Ready Interrupt has occurred
  [4] SSC2RDY — DMA Channel 3 Interrupt Status (SSCx Receive)
    0=No DMA SSCx Transfer Ready Interrupt has occurred; 1=DMA SSCx Transfer Ready Interrupt has occurred
  [3] SSC1RDY — DMA Channel 2 Interrupt Status (SSCx Transmit)
    values as SSC2RDY
  [2] TRSEQ2DY — DMA Channel 1 Interrupt Status (ADC1 ESM)
    0=No Transfer Sequence Ready Interrupt has occurred; 1=Transfer Sequence Ready Interrupt has occurred
  [1] TRSEQ1DY — DMA Channel 0 Interrupt Status (ADC1 Sequence)
    values as TRSEQ2DY
  [0] STRDY — DMA Single Transfer Ready
    0=No Single Transfer Interrupt has occurred; 1=Single Transfer Ready Interrupt has occurred
0x15C GPT12IEN reset 0x3F — General Purpose Timer 12 Interrupt Enable Register , RESET_TYPE_3
  [all] fields
    0=Interrupt is disabled; 1=Interrupt is enabled
  [5] CRIE — General Purpose Timer 12 Capture and Reload Interrupt Enable
  [n-2] T{n}IE (n=2..6) — General Purpose Timer 12 T{n} Interrupt Enable
0x160 GPT12IRC ro — Timer and Counter Control/Status Register, RESET_TYPE_3
  [5] CR — GPT Module 2 Capture Reload Interrupt Status
    0=No Capture Reload Interrupt has occurred; 1=Capture Reload Interrupt has occurred
  [4] T6 — GPT Module 2Timer6 Interrupt Status
    0=No Timer 6 Interrupt has occurred; 1=Timer 6 Interrupt has occurred
  [3] T5 — GPT Module 2 Timer5 Interrupt Status
    0=No Timer 5 Interrupt has occurred; 1=Timer 5 Interrupt has occurred
  [2] T4 — GPT Module 1 Timer4 Interrupt Status
    0=No Timer 4 Interrupt has occurred; 1=Timer 4 Interrupt has occurred
  [1] T3 — GPT Module 1 Timer3 Interrupt Status
    0=No Timer 3 Interrupt has occurred; 1=Timer 3 Interrupt has occurred
  [0] T2 — GPT Module 1 Timer 2 Interrupt Status
    0=No Timer 2 Interrupt has occurred; 1=Timer 2 Interrupt has occurred
0x164 GPT12ICLR wo — Timer and Counter Control/Status Clear Register, RESET_TYPE_3
  [5] CRC — GPT Module 2 Capture Reload Interrupt Status Clear
    0=No Capture Reload Interrupt is cleared; 1=Capture Reload Interrupt is cleared
  [4] T6C — GPT Module 2Timer6 Interrupt Status Clear
    0=No Timer 6 Interrupt is cleared; 1=Timer 6 Interrupt is cleared
  [3] T5C — GPT Module 2 Timer5 Interrupt Status Clear
    0=No Timer 5 Interrupt is cleared; 1=Timer 5 Interrupt is cleared
  [2] T4C — GPT Module 1 Timer4 Interrupt Status Clear
    0=No Timer 4 Interrupt is cleared; 1=Timer 4 Interrupt is cleared
  [1] T3C — GPT Module 1 Timer3 Interrupt Status Clear
    0=No Timer 3 Interrupt is cleared; 1=Timer 3 Interrupt is cleared
  [0] T2C — GPT Module 1 Timer 2 Interrupt Status Clear
    0=No Timer 2 Interrupt is cleared; 1=Timer 2 Interrupt is cleared
0x178 IRCON1CLR wo — Interrupt Request 1 Clear Register, RESET_TYPE_3
  [all] fields
    0=Interrupt event is not cleared; 1=Interrupt event is cleared
  [2] RIRC — Receive Interrupt Flag for SSC1 Clear
  [1] TIRC — Transmit Interrupt Flag for SSC1 Clear
  [0] EIRC — Error Interrupt Flag for SSC1 Clear
0x17C IRCON2CLR wo — Interrupt Request 2 Clear Register, RESET_TYPE_3
  [all] fields
    values as the fields of IRCON1CLR
  [2] RIRC — Receive Interrupt Flag for SSC2 Clear
  [1] TIRC — Transmit Interrupt Flag for SSC2 Clear
  [0] EIRC — Error Interrupt Flag for SSC2 Clear
0x180 DMASRCSEL2 — DMA Source Selection Register 2, RESET_TYPE_3
  [1:0] GPT12_DMAEN — GPT12 T3 DMA muxer, DMA channel 12
    0=Timer3 cc6u_int used as DMA channel 12; 1=GPT12 T3 used as DMA channel 12; 2=Timer3 ccu6_int or T12_ZM used as DMA channel 12; 3=GPT12 T3 or T12_ZM used as DMA channel 12
0x184 DMAIRC1CLR wo — DMA Interrupt Control 1 Clear Register, RESET_TYPE_3
  [n-1] CH{n}C (n=1..8) — DMA Channel {n+3} Interrupt Status Clear (ADC1 Channel {n-1})
    0=No DMA Channel {n+3} Interrupt is cleared; 1=DMA Channel {n+3} Interrupt is cleared
0x188 DMAIRC2CLR wo — ADC1 Interrupt Control 2 Clear Register, RESET_TYPE_3
  [6] SDADCC — DMA Channel 13 Interrupt Status Clear (SDADC)
    0=No DMA SDADC Transfer Ready Interrupt is cleared; 1=DMA SDADC Transfer Ready Interrupt is cleared
  [5] GPT12C — DMA Channel 12 Interrupt Status Clear (GPT12/Timer3)
    0=No DMA GPT12 Transfer Ready Interrupt is cleared; 1=DMA GPT12 Transfer Ready Interrupt is cleared
  [4] SSC2C — DMA Channel 3 Interrupt Status Clear (SSCx Receive)
    0=No DMA SSCx Transfer Ready Interrupt is cleared; 1=DMA SSCx Transfer Ready Interrupt is cleared
  [3] SSC1C — DMA Channel 2 Interrupt Status Clear (SSCx Transmit)
    values as SSC2C
  [2] TRSEQ2DYC — DMA Channel 1 Interrupt Status Clear (ADC1 ESM)
    0=No Transfer Sequence Ready Interrupt is cleared; 1=Transfer Sequence Ready Interrupt is cleared
  [1] TRSEQ1DYC — DMA Channel 0 Interrupt Status Clear (ADC1 Sequence)
    values as TRSEQ2DYC
0x190 IRCON3CLR wo — Interrupt Request 3 Clear Register, RESET_TYPE_3
  [4] CCU6SR1C — Interrupt Flag 1 for CCU6 Clear
    values as the fields of IRCON1CLR
  [0] CCU6SR0C — Interrupt Flag 0 for CCU6 Clear
    values as the fields of IRCON1CLR
0x194 IRCON4CLR wo — Interrupt Request 4 Clear Register, RESET_TYPE_3
  [4] CCU6SR3C — Interrupt Flag 3 for CCU6 Clear
    values as the fields of IRCON1CLR
  [0] CCU6SR2C — Interrupt Flag 2 for CCU6 Clear
    values as the fields of IRCON1CLR
0x198 DMASRCCLR wo — DMA Source Selection Clear Register, RESET_TYPE_3
  [7] GPT12_T3C — GPT12 Transmit Request Clear
    0=GPT12_T3 Transfer DMA Request not cleared; 1=GPT12_T3 Transfer DMA Request cleared
  [6] SSCRXC — SSC Receive Request Clear
    0=SSC Receive DMA Request not cleared; 1=SSC Receive DMA Request cleared
  [5] SSCTXC — SSC Transmit Request Clear
    0=SSC Transmit DMA Request not cleared; 1=SSC Transmit DMA Request cleared
